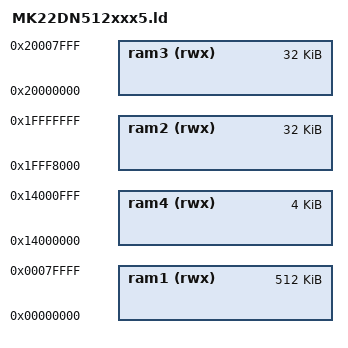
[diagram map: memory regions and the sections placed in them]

MEMORY
{
  ram1 (rwx) : ORIGIN = 0x00000000, LENGTH = 0x080000
  ram2 (rwx) : ORIGIN = 0x1fff8000, LENGTH = 0x8000
  ram3 (rwx) : ORIGIN = 0x20000000, LENGTH = 0x8000
  ram4 (rwx) : ORIGIN = 0x14000000, LENGTH = 0x1000
}

